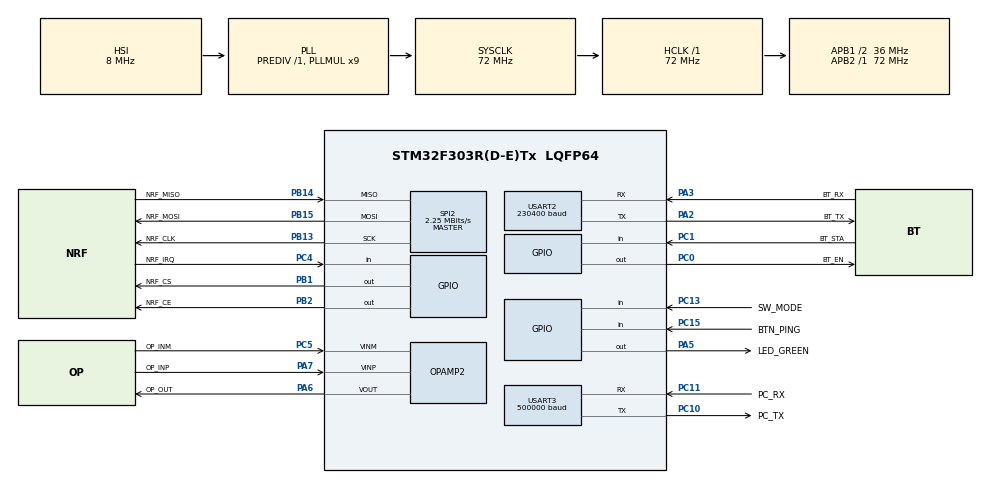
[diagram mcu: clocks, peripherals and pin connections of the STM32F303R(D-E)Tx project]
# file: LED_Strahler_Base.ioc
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ADC2.Channel-0\#ChannelRegularConversion=ADC_CHANNEL_3
ADC2.NbrOfConversionFlag=1
ADC2.Offset-0\#ChannelRegularConversion=0
ADC2.OffsetNumber-0\#ChannelRegularConversion=ADC_OFFSET_NONE
ADC2.Rank-0\#ChannelRegularConversion=1
ADC2.SamplingTime-0\#ChannelRegularConversion=ADC_SAMPLETIME_1CYCLE_5
Dma.Request0=USART2_RX
Dma.Request1=USART2_TX
Dma.Request2=USART3_RX
Dma.Request3=USART3_TX
Dma.USART2_RX.0.Direction=DMA_PERIPH_TO_MEMORY
Dma.USART2_RX.0.Instance=DMA1_Channel6
Dma.USART2_RX.0.MemDataAlignment=DMA_MDATAALIGN_BYTE
Dma.USART2_RX.0.MemInc=DMA_MINC_ENABLE
Dma.USART2_RX.0.Mode=DMA_CIRCULAR
Dma.USART2_RX.0.PeriphDataAlignment=DMA_PDATAALIGN_BYTE
Dma.USART2_RX.0.PeriphInc=DMA_PINC_DISABLE
Dma.USART2_RX.0.Priority=DMA_PRIORITY_HIGH
Dma.USART2_TX.1.Direction=DMA_MEMORY_TO_PERIPH
Dma.USART2_TX.1.Instance=DMA1_Channel7
Dma.USART2_TX.1.MemDataAlignment=DMA_MDATAALIGN_BYTE
Dma.USART2_TX.1.MemInc=DMA_MINC_ENABLE
Dma.USART2_TX.1.Mode=DMA_NORMAL
Dma.USART2_TX.1.PeriphDataAlignment=DMA_PDATAALIGN_BYTE
Dma.USART2_TX.1.PeriphInc=DMA_PINC_DISABLE
Dma.USART2_TX.1.Priority=DMA_PRIORITY_LOW
Dma.USART3_RX.2.Direction=DMA_PERIPH_TO_MEMORY
Dma.USART3_RX.2.Instance=DMA1_Channel3
Dma.USART3_RX.2.MemDataAlignment=DMA_MDATAALIGN_BYTE
Dma.USART3_RX.2.MemInc=DMA_MINC_ENABLE
Dma.USART3_RX.2.Mode=DMA_CIRCULAR
Dma.USART3_RX.2.PeriphDataAlignment=DMA_PDATAALIGN_BYTE
Dma.USART3_RX.2.PeriphInc=DMA_PINC_DISABLE
Dma.USART3_RX.2.Priority=DMA_PRIORITY_VERY_HIGH
Dma.USART3_TX.3.Direction=DMA_MEMORY_TO_PERIPH
Dma.USART3_TX.3.Instance=DMA1_Channel2
Dma.USART3_TX.3.MemDataAlignment=DMA_MDATAALIGN_BYTE
Dma.USART3_TX.3.MemInc=DMA_MINC_ENABLE
Dma.USART3_TX.3.Mode=DMA_NORMAL
Dma.USART3_TX.3.PeriphDataAlignment=DMA_PDATAALIGN_BYTE
Dma.USART3_TX.3.PeriphInc=DMA_PINC_DISABLE
Dma.USART3_TX.3.Priority=DMA_PRIORITY_MEDIUM
Mcu.Family=STM32F3
Mcu.Name=STM32F303R(D-E)Tx
Mcu.Package=LQFP64
NVIC.DMA1_Channel2_IRQn=true\:0\:0\:false\:false\:true\:false\:true
NVIC.DMA1_Channel3_IRQn=true\:0\:0\:false\:false\:true\:false\:true
NVIC.DMA1_Channel6_IRQn=true\:0\:0\:false\:false\:true\:false\:true
NVIC.DMA1_Channel7_IRQn=true\:0\:0\:false\:false\:true\:false\:true
NVIC.PriorityGroup=NVIC_PRIORITYGROUP_0
NVIC.SPI2_IRQn=true\:0\:0\:false\:false\:true\:true\:true
NVIC.USART2_IRQn=true\:0\:6\:false\:false\:true\:true\:true
NVIC.USART3_IRQn=true\:0\:6\:false\:false\:true\:true\:true
PA13.GPIO_Label=SWDIO
PA13.Mode=Serial_Wire
PA13.Signal=SYS_JTMS-SWDIO
PA14.GPIO_Label=SWDCLK
PA14.Mode=Serial_Wire
PA14.Signal=SYS_JTCK-SWCLK
PA2.GPIO_Label=BT_TX
PA2.GPIO_Mode=GPIO_MODE_AF_PP
PA2.GPIO_PuPd=GPIO_NOPULL
PA2.GPIO_Speed=GPIO_SPEED_FREQ_MEDIUM
PA2.Mode=Asynchronous
PA2.Signal=USART2_TX
PA3.GPIO_Label=BT_RX
PA3.GPIO_Mode=GPIO_MODE_AF_PP
PA3.GPIO_PuPd=GPIO_PULLUP
PA3.GPIO_Speed=GPIO_SPEED_FREQ_LOW
PA3.Mode=Asynchronous
PA3.Signal=USART2_RX
PA5.GPIO_Label=LED_GREEN
PA5.GPIO_Mode=GPIO_MODE_OUTPUT_PP
PA5.GPIO_PuPd=GPIO_NOPULL
PA5.GPIO_Speed=GPIO_SPEED_FREQ_LOW
PA5.Signal=GPIO_Output
PA6.GPIO_Label=OP_OUT
PA6.Signal=SharedAnalog_PA6
PA7.GPIO_Label=OP_INP
PA7.Mode=PGA Connected
PA7.Signal=OPAMP2_VINP
PB1.GPIO_Label=NRF_CS
PB1.GPIO_Speed=GPIO_SPEED_FREQ_MEDIUM
PB1.PinState=GPIO_PIN_SET
PB1.Signal=GPIO_Output
PB13.GPIO_Label=NRF_CLK
PB13.GPIO_Speed=GPIO_SPEED_FREQ_MEDIUM
PB13.Mode=Full_Duplex_Master
PB13.Signal=SPI2_SCK
PB14.GPIO_Label=NRF_MISO
PB14.GPIO_PuPd=GPIO_PULLUP
PB14.GPIO_Speed=GPIO_SPEED_FREQ_MEDIUM
PB14.Mode=Full_Duplex_Master
PB14.Signal=SPI2_MISO
PB15.GPIO_Label=NRF_MOSI
PB15.GPIO_Speed=GPIO_SPEED_FREQ_MEDIUM
PB15.Mode=Full_Duplex_Master
PB15.Signal=SPI2_MOSI
PB2.GPIO_Label=NRF_CE
PB2.GPIO_Speed=GPIO_SPEED_FREQ_MEDIUM
PB2.Signal=GPIO_Output
PC0.GPIO_Label=BT_EN
PC0.PinState=GPIO_PIN_SET
PC0.Signal=GPIO_Output
PC1.GPIO_Label=BT_STA
PC1.GPIO_PuPd=GPIO_PULLUP
PC1.Signal=GPIO_Input
PC10.GPIO_Label=PC_TX
PC10.GPIO_Speed=GPIO_SPEED_FREQ_MEDIUM
PC10.Mode=Asynchronous
PC10.Signal=USART3_TX
PC11.GPIO_Label=PC_RX
PC11.GPIO_PuPd=GPIO_PULLUP
PC11.GPIO_Speed=GPIO_SPEED_FREQ_LOW
PC11.Mode=Asynchronous
PC11.Signal=USART3_RX
PC13.GPIO_Label=SW_MODE
PC13.GPIO_PuPd=GPIO_PULLUP
PC13.Signal=GPIO_Input
PC15-OSC32_OUT.GPIO_Label=BTN_PING
PC15-OSC32_OUT.GPIO_PuPd=GPIO_PULLUP
PC15-OSC32_OUT.Signal=GPIO_Input
PC4.GPIO_Label=NRF_IRQ
PC4.GPIO_PuPd=GPIO_PULLUP
PC4.Signal=GPIO_Input
PC5.GPIO_Label=OP_INM
PC5.Mode=PGA Connected
PC5.Signal=OPAMP2_VINM
PF0-OSC_IN.Mode=HSE-External-Oscillator
PF0-OSC_IN.Signal=RCC_OSC_IN
PF1-OSC_OUT.Mode=HSE-External-Oscillator
PF1-OSC_OUT.Signal=RCC_OSC_OUT
ProjectManager.HeapSize=0x200
ProjectManager.StackSize=0x400
ProjectManager.TargetToolchain=STM32CubeIDE
RCC.AHBFreq_Value=72000000
RCC.APB1CLKDivider=RCC_HCLK_DIV2
RCC.APB1Freq_Value=36000000
RCC.APB1TimFreq_Value=72000000
RCC.APB2Freq_Value=72000000
RCC.APB2TimFreq_Value=72000000
RCC.CortexFreq_Value=9000000
RCC.Cortex_Div=SYSTICK_CLKSOURCE_HCLK_DIV8
RCC.HCLKFreq_Value=72000000
RCC.HSE_VALUE=8000000
RCC.HSI_VALUE=8000000
RCC.LSE_VALUE=32768
RCC.PLLM=8
RCC.PLLMUL=RCC_PLL_MUL9
RCC.PLLN=336
RCC.PLLP=RCC_PLLP_DIV4
RCC.PLLQ=7
RCC.RCC_PLLsource_Clock_Source_FROM_HSE=RCC_HSE_PREDIV_DIV2
RCC.SYSCLKFreq_VALUE=72000000
RCC.SYSCLKSourceVirtual=RCC_SYSCLKSOURCE_PLLCLK
RCC.USBFreq_Value=72000000
SH.SharedAnalog_PA6.0=ADC2_IN3
SH.SharedAnalog_PA6.1=OPAMP2_VOUT,PGA Connected
SPI2.BaudRatePrescaler=SPI_BAUDRATEPRESCALER_16
SPI2.CLKPolarity=SPI_POLARITY_LOW
SPI2.CalculateBaudRate=2.25 MBits/s
SPI2.DataSize=SPI_DATASIZE_8BIT
SPI2.Direction=SPI_DIRECTION_2LINES
SPI2.Mode=SPI_MODE_MASTER
SPI2.NSSPMode=SPI_NSS_PULSE_DISABLE
SPI2.VirtualType=VM_MASTER
USART2.BaudRate=230400
USART2.VirtualMode-Asynchronous=VM_ASYNC
USART3.BaudRate=500000
USART3.VirtualMode-Asynchronous=VM_ASYNC
VP_ADC2_OPAMP_OUT2.Mode=IN3-OPAMP2-Single-Ended
board=NUCLEO-F303RE

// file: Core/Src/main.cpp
/* USER CODE BEGIN Header */
/**
  ******************************************************************************
  * @file           : main.c
  * @brief          : Main program body
  ******************************************************************************
  * @attention
  *
  * <h2><center>&copy; Copyright (c) 2019 STMicroelectronics.
  * All rights reserved.</center></h2>
  *
  * This software component is licensed by ST under BSD 3-Clause license,
  * the "License"; You may not use this file except in compliance with the
  * License. You may obtain a copy of the License at:
  *                        opensource.org/licenses/BSD-3-Clause
  *
  ******************************************************************************
  */
/* USER CODE END Header */

#include "main.h"

/* USER CODE BEGIN Includes */
#include "LED_Base.h"
/* USER CODE END Includes */

ADC_HandleTypeDef hadc2;

OPAMP_HandleTypeDef hopamp2;

SPI_HandleTypeDef hspi2;

UART_HandleTypeDef huart2;
UART_HandleTypeDef huart3;
DMA_HandleTypeDef hdma_usart2_rx;
DMA_HandleTypeDef hdma_usart2_tx;
DMA_HandleTypeDef hdma_usart3_rx;
DMA_HandleTypeDef hdma_usart3_tx;

void SystemClock_Config(void);
static void MX_GPIO_Init(void);
static void MX_USART2_UART_Init(void);
static void MX_DMA_Init(void);
static void MX_ADC2_Init(void);
static void MX_OPAMP2_Init(void);
static void MX_SPI2_Init(void);
static void MX_USART3_UART_Init(void);

int main(void)
{

  /* MCU Configuration--------------------------------------------------------*/

  /* Reset of all peripherals, Initializes the Flash interface and the Systick. */
  HAL_Init();

  /* Configure the system clock */
  SystemClock_Config();

  /* Initialize all configured peripherals */
  MX_GPIO_Init();
  MX_USART2_UART_Init();
  MX_DMA_Init();
  MX_ADC2_Init();
  MX_OPAMP2_Init();
  MX_SPI2_Init();
  MX_USART3_UART_Init();
  /* USER CODE BEGIN 2 */
  LED_Base_Setup();
  /* USER CODE END 2 */

  /* Infinite loop */
  /* USER CODE BEGIN WHILE */
  while (1)
  {
 	LED_Base_Handle();
    /* USER CODE END WHILE */

  }
}

void SystemClock_Config(void)
{
  RCC_OscInitTypeDef RCC_OscInitStruct = {0};
  RCC_ClkInitTypeDef RCC_ClkInitStruct = {0};
  RCC_PeriphCLKInitTypeDef PeriphClkInit = {0};

  /** Initializes the CPU, AHB and APB busses clocks
  */
  RCC_OscInitStruct.OscillatorType = RCC_OSCILLATORTYPE_HSI;
  RCC_OscInitStruct.HSIState = RCC_HSI_ON;
  RCC_OscInitStruct.HSICalibrationValue = RCC_HSICALIBRATION_DEFAULT;
  RCC_OscInitStruct.PLL.PLLState = RCC_PLL_ON;
  RCC_OscInitStruct.PLL.PLLSource = RCC_PLLSOURCE_HSI;
  RCC_OscInitStruct.PLL.PLLMUL = RCC_PLL_MUL9;
  RCC_OscInitStruct.PLL.PREDIV = RCC_PREDIV_DIV1;
  if (HAL_RCC_OscConfig(&RCC_OscInitStruct) != HAL_OK)
  {
    Error_Handler();
  }
  /** Initializes the CPU, AHB and APB busses clocks
  */
  RCC_ClkInitStruct.ClockType = RCC_CLOCKTYPE_HCLK|RCC_CLOCKTYPE_SYSCLK
                              |RCC_CLOCKTYPE_PCLK1|RCC_CLOCKTYPE_PCLK2;
  RCC_ClkInitStruct.SYSCLKSource = RCC_SYSCLKSOURCE_PLLCLK;
  RCC_ClkInitStruct.AHBCLKDivider = RCC_SYSCLK_DIV1;
  RCC_ClkInitStruct.APB1CLKDivider = RCC_HCLK_DIV2;
  RCC_ClkInitStruct.APB2CLKDivider = RCC_HCLK_DIV1;

  if (HAL_RCC_ClockConfig(&RCC_ClkInitStruct, FLASH_LATENCY_2) != HAL_OK)
  {
    Error_Handler();
  }
  PeriphClkInit.PeriphClockSelection = RCC_PERIPHCLK_USART2|RCC_PERIPHCLK_USART3
                              |RCC_PERIPHCLK_ADC12;
  PeriphClkInit.Usart2ClockSelection = RCC_USART2CLKSOURCE_PCLK1;
  PeriphClkInit.Usart3ClockSelection = RCC_USART3CLKSOURCE_PCLK1;
  PeriphClkInit.Adc12ClockSelection = RCC_ADC12PLLCLK_DIV1;
  if (HAL_RCCEx_PeriphCLKConfig(&PeriphClkInit) != HAL_OK)
  {
    Error_Handler();
  }
}

static void MX_ADC2_Init(void)
{

  ADC_ChannelConfTypeDef sConfig = {0};

  /** Common config
  */
  hadc2.Instance = ADC2;
  hadc2.Init.ClockPrescaler = ADC_CLOCK_ASYNC_DIV1;
  hadc2.Init.Resolution = ADC_RESOLUTION_12B;
  hadc2.Init.ScanConvMode = ADC_SCAN_DISABLE;
  hadc2.Init.ContinuousConvMode = DISABLE;
  hadc2.Init.DiscontinuousConvMode = DISABLE;
  hadc2.Init.ExternalTrigConvEdge = ADC_EXTERNALTRIGCONVEDGE_NONE;
  hadc2.Init.ExternalTrigConv = ADC_SOFTWARE_START;
  hadc2.Init.DataAlign = ADC_DATAALIGN_RIGHT;
  hadc2.Init.NbrOfConversion = 1;
  hadc2.Init.DMAContinuousRequests = DISABLE;
  hadc2.Init.EOCSelection = ADC_EOC_SINGLE_CONV;
  hadc2.Init.LowPowerAutoWait = DISABLE;
  hadc2.Init.Overrun = ADC_OVR_DATA_OVERWRITTEN;
  if (HAL_ADC_Init(&hadc2) != HAL_OK)
  {
    Error_Handler();
  }
  /** Configure Regular Channel
  */
  sConfig.Channel = ADC_CHANNEL_3;
  sConfig.Rank = ADC_REGULAR_RANK_1;
  sConfig.SingleDiff = ADC_SINGLE_ENDED;
  sConfig.SamplingTime = ADC_SAMPLETIME_1CYCLE_5;
  sConfig.OffsetNumber = ADC_OFFSET_NONE;
  sConfig.Offset = 0;
  if (HAL_ADC_ConfigChannel(&hadc2, &sConfig) != HAL_OK)
  {
    Error_Handler();
  }

}

static void MX_OPAMP2_Init(void)
{

  hopamp2.Instance = OPAMP2;
  hopamp2.Init.Mode = OPAMP_PGA_MODE;
  hopamp2.Init.NonInvertingInput = OPAMP_NONINVERTINGINPUT_IO0;
  hopamp2.Init.TimerControlledMuxmode = OPAMP_TIMERCONTROLLEDMUXMODE_DISABLE;
  hopamp2.Init.PgaConnect = OPAMP_PGA_CONNECT_INVERTINGINPUT_IO0;
  hopamp2.Init.PgaGain = OPAMP_PGA_GAIN_2;
  hopamp2.Init.UserTrimming = OPAMP_TRIMMING_FACTORY;
  if (HAL_OPAMP_Init(&hopamp2) != HAL_OK)
  {
    Error_Handler();
  }

}

static void MX_SPI2_Init(void)
{

  /* SPI2 parameter configuration*/
  hspi2.Instance = SPI2;
  hspi2.Init.Mode = SPI_MODE_MASTER;
  hspi2.Init.Direction = SPI_DIRECTION_2LINES;
  hspi2.Init.DataSize = SPI_DATASIZE_8BIT;
  hspi2.Init.CLKPolarity = SPI_POLARITY_LOW;
  hspi2.Init.CLKPhase = SPI_PHASE_1EDGE;
  hspi2.Init.NSS = SPI_NSS_SOFT;
  hspi2.Init.BaudRatePrescaler = SPI_BAUDRATEPRESCALER_16;
  hspi2.Init.FirstBit = SPI_FIRSTBIT_MSB;
  hspi2.Init.TIMode = SPI_TIMODE_DISABLE;
  hspi2.Init.CRCCalculation = SPI_CRCCALCULATION_DISABLE;
  hspi2.Init.CRCPolynomial = 7;
  hspi2.Init.CRCLength = SPI_CRC_LENGTH_DATASIZE;
  hspi2.Init.NSSPMode = SPI_NSS_PULSE_DISABLE;
  if (HAL_SPI_Init(&hspi2) != HAL_OK)
  {
    Error_Handler();
  }
  /* USER CODE BEGIN SPI2_Init 2 */
  /* full duplex master, 8 bit transfer, default phase and polarity */
  hspi2.Instance->CR1 |= SPI_CR1_MSTR | SPI_CR1_SPE | SPI_CR1_SSM | SPI_CR1_SSI;
  /* Disable receive FIFO, it'd complicate things when there is an odd number of bytes to transfer */
  hspi2.Instance->CR2 |= SPI_CR2_FRXTH;
  /* USER CODE END SPI2_Init 2 */

}

static void MX_USART2_UART_Init(void)
{

  huart2.Instance = USART2;
  huart2.Init.BaudRate = 230400;
  huart2.Init.WordLength = UART_WORDLENGTH_8B;
  huart2.Init.StopBits = UART_STOPBITS_1;
  huart2.Init.Parity = UART_PARITY_NONE;
  huart2.Init.Mode = UART_MODE_TX_RX;
  huart2.Init.HwFlowCtl = UART_HWCONTROL_NONE;
  huart2.Init.OverSampling = UART_OVERSAMPLING_16;
  huart2.Init.OneBitSampling = UART_ONE_BIT_SAMPLE_DISABLE;
  huart2.AdvancedInit.AdvFeatureInit = UART_ADVFEATURE_NO_INIT;
  if (HAL_UART_Init(&huart2) != HAL_OK)
  {
    Error_Handler();
  }

}

static void MX_USART3_UART_Init(void)
{

  huart3.Instance = USART3;
  huart3.Init.BaudRate = 500000;
  huart3.Init.WordLength = UART_WORDLENGTH_8B;
  huart3.Init.StopBits = UART_STOPBITS_1;
  huart3.Init.Parity = UART_PARITY_NONE;
  huart3.Init.Mode = UART_MODE_TX_RX;
  huart3.Init.HwFlowCtl = UART_HWCONTROL_NONE;
  huart3.Init.OverSampling = UART_OVERSAMPLING_16;
  huart3.Init.OneBitSampling = UART_ONE_BIT_SAMPLE_DISABLE;
  huart3.AdvancedInit.AdvFeatureInit = UART_ADVFEATURE_NO_INIT;
  if (HAL_UART_Init(&huart3) != HAL_OK)
  {
    Error_Handler();
  }

}

static void MX_DMA_Init(void)
{

  /* DMA controller clock enable */
  __HAL_RCC_DMA1_CLK_ENABLE();

  /* DMA interrupt init */
  /* DMA1_Channel2_IRQn interrupt configuration */
  HAL_NVIC_SetPriority(DMA1_Channel2_IRQn, 0, 0);
  HAL_NVIC_EnableIRQ(DMA1_Channel2_IRQn);
  /* DMA1_Channel3_IRQn interrupt configuration */
  HAL_NVIC_SetPriority(DMA1_Channel3_IRQn, 0, 0);
  HAL_NVIC_EnableIRQ(DMA1_Channel3_IRQn);
  /* DMA1_Channel6_IRQn interrupt configuration */
  HAL_NVIC_SetPriority(DMA1_Channel6_IRQn, 0, 0);
  HAL_NVIC_EnableIRQ(DMA1_Channel6_IRQn);
  /* DMA1_Channel7_IRQn interrupt configuration */
  HAL_NVIC_SetPriority(DMA1_Channel7_IRQn, 0, 0);
  HAL_NVIC_EnableIRQ(DMA1_Channel7_IRQn);

}

static void MX_GPIO_Init(void)
{
  GPIO_InitTypeDef GPIO_InitStruct = {0};

  /* GPIO Ports Clock Enable */
  __HAL_RCC_GPIOC_CLK_ENABLE();
  __HAL_RCC_GPIOF_CLK_ENABLE();
  __HAL_RCC_GPIOA_CLK_ENABLE();
  __HAL_RCC_GPIOB_CLK_ENABLE();

  /*Configure GPIO pin Output Level */
  HAL_GPIO_WritePin(BT_EN_GPIO_Port, BT_EN_Pin, GPIO_PIN_SET);

  /*Configure GPIO pin Output Level */
  HAL_GPIO_WritePin(LED_GREEN_GPIO_Port, LED_GREEN_Pin, GPIO_PIN_RESET);

  /*Configure GPIO pin Output Level */
  HAL_GPIO_WritePin(NRF_CS_GPIO_Port, NRF_CS_Pin, GPIO_PIN_SET);

  /*Configure GPIO pin Output Level */
  HAL_GPIO_WritePin(NRF_CE_GPIO_Port, NRF_CE_Pin, GPIO_PIN_RESET);

  /*Configure GPIO pins : SW_MODE_Pin BTN_PING_Pin BT_STA_Pin NRF_IRQ_Pin */
  GPIO_InitStruct.Pin = SW_MODE_Pin|BTN_PING_Pin|BT_STA_Pin|NRF_IRQ_Pin;
  GPIO_InitStruct.Mode = GPIO_MODE_INPUT;
  GPIO_InitStruct.Pull = GPIO_PULLUP;
  HAL_GPIO_Init(GPIOC, &GPIO_InitStruct);

  /*Configure GPIO pin : BT_EN_Pin */
  GPIO_InitStruct.Pin = BT_EN_Pin;
  GPIO_InitStruct.Mode = GPIO_MODE_OUTPUT_PP;
  GPIO_InitStruct.Pull = GPIO_NOPULL;
  GPIO_InitStruct.Speed = GPIO_SPEED_FREQ_LOW;
  HAL_GPIO_Init(BT_EN_GPIO_Port, &GPIO_InitStruct);

  /*Configure GPIO pin : LED_GREEN_Pin */
  GPIO_InitStruct.Pin = LED_GREEN_Pin;
  GPIO_InitStruct.Mode = GPIO_MODE_OUTPUT_PP;
  GPIO_InitStruct.Pull = GPIO_NOPULL;
  GPIO_InitStruct.Speed = GPIO_SPEED_FREQ_LOW;
  HAL_GPIO_Init(LED_GREEN_GPIO_Port, &GPIO_InitStruct);

  /*Configure GPIO pins : NRF_CS_Pin NRF_CE_Pin */
  GPIO_InitStruct.Pin = NRF_CS_Pin|NRF_CE_Pin;
  GPIO_InitStruct.Mode = GPIO_MODE_OUTPUT_PP;
  GPIO_InitStruct.Pull = GPIO_NOPULL;
  GPIO_InitStruct.Speed = GPIO_SPEED_FREQ_MEDIUM;
  HAL_GPIO_Init(GPIOB, &GPIO_InitStruct);

}

void Error_Handler(void)
{
}

/************************ (C) COPYRIGHT STMicroelectronics *****END OF FILE****/
